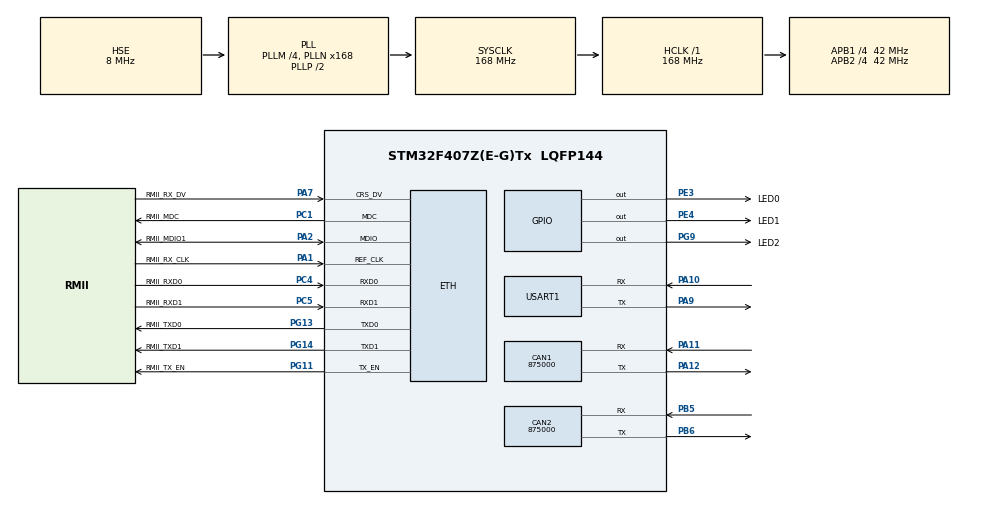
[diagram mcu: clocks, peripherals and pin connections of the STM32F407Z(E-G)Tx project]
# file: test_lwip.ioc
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CAN1.CalculateBaudRate=875000
CAN1.CalculateTimeBit=1142
CAN1.CalculateTimeQuantum=380.95238095238096
CAN2.CalculateBaudRate=875000
CAN2.CalculateTimeBit=1142
CAN2.CalculateTimeQuantum=380.95238095238096
Dma.Request0=USART1_RX
Dma.Request1=USART1_TX
Dma.USART1_RX.0.Direction=DMA_PERIPH_TO_MEMORY
Dma.USART1_RX.0.FIFOMode=DMA_FIFOMODE_DISABLE
Dma.USART1_RX.0.Instance=DMA2_Stream2
Dma.USART1_RX.0.MemDataAlignment=DMA_MDATAALIGN_BYTE
Dma.USART1_RX.0.MemInc=DMA_MINC_ENABLE
Dma.USART1_RX.0.Mode=DMA_NORMAL
Dma.USART1_RX.0.PeriphDataAlignment=DMA_PDATAALIGN_BYTE
Dma.USART1_RX.0.PeriphInc=DMA_PINC_DISABLE
Dma.USART1_RX.0.Priority=DMA_PRIORITY_LOW
Dma.USART1_TX.1.Direction=DMA_MEMORY_TO_PERIPH
Dma.USART1_TX.1.FIFOMode=DMA_FIFOMODE_DISABLE
Dma.USART1_TX.1.Instance=DMA2_Stream7
Dma.USART1_TX.1.MemDataAlignment=DMA_MDATAALIGN_BYTE
Dma.USART1_TX.1.MemInc=DMA_MINC_ENABLE
Dma.USART1_TX.1.Mode=DMA_NORMAL
Dma.USART1_TX.1.PeriphDataAlignment=DMA_PDATAALIGN_BYTE
Dma.USART1_TX.1.PeriphInc=DMA_PINC_DISABLE
Dma.USART1_TX.1.Priority=DMA_PRIORITY_LOW
ETH.MediaInterface=HAL_ETH_RMII_MODE
ETH.PHY_Name_RMII=DP83848_PHY_ADDRESS
FREERTOS.INCLUDE_vTaskDelayUntil=1
FREERTOS.Tasks01=defaultTask,0,256,StartDefaultTask,Default,NULL,Dynamic,NULL,NULL
FREERTOS.configMINIMAL_STACK_SIZE=256
LWIP.BSP.number=1
LWIP.GATEWAY_ADDRESS=010.043.060.001
LWIP.IP_ADDRESS=010.043.060.170
LWIP.LWIP_DHCP=0
LWIP.LWIP_NETIF_LOOPBACK=0
LWIP.MEM_SIZE=16360
LWIP.NETMASK_ADDRESS=255.255.255.000
LWIP.Version=v2.1.2_Cube
LWIP0.BSP.STBoard=false
LWIP0.BSP.api=BSP_COMPONENT_DRIVER
LWIP0.BSP.component=DP83848
LWIP0.BSP.instance=DP83848
LWIP0.BSP.name=Driver_PHY
LWIP0.BSP.semaphore=S_DP83848
LWIP0.BSP.solution=DP83848
Mcu.Family=STM32F4
Mcu.Name=STM32F407Z(E-G)Tx
Mcu.Package=LQFP144
NVIC.DMA2_Stream2_IRQn=true\:5\:0\:false\:false\:true\:true\:false\:true\:true
NVIC.DMA2_Stream7_IRQn=true\:5\:0\:false\:false\:true\:true\:false\:true\:true
NVIC.ETH_IRQn=true\:5\:0\:false\:false\:true\:true\:false\:true\:true
NVIC.PriorityGroup=NVIC_PRIORITYGROUP_4
NVIC.TIM4_IRQn=true\:15\:0\:false\:false\:true\:false\:false\:true\:true
NVIC.TimeBase=TIM4_IRQn
NVIC.TimeBaseIP=TIM4
NVIC.USART1_IRQn=true\:5\:0\:false\:false\:true\:true\:true\:true\:true
PA1.GPIO_Label=RMII_RX_CLK
PA1.Mode=RMII
PA1.Signal=ETH_REF_CLK
PA10.Mode=Asynchronous
PA10.Signal=USART1_RX
PA11.Mode=CAN_Activate
PA11.Signal=CAN1_RX
PA12.Mode=CAN_Activate
PA12.Signal=CAN1_TX
PA13.Mode=Trace_Asynchronous_SW
PA13.Signal=SYS_JTMS-SWDIO
PA14.Mode=Trace_Asynchronous_SW
PA14.Signal=SYS_JTCK-SWCLK
PA2.GPIO_Label=RMII_MDIO1
PA2.Mode=RMII
PA2.Signal=ETH_MDIO
PA7.GPIO_Label=RMII_RX_DV
PA7.Mode=RMII
PA7.Signal=ETH_CRS_DV
PA9.Mode=Asynchronous
PA9.Signal=USART1_TX
PB3.Mode=Trace_Asynchronous_SW
PB3.Signal=SYS_JTDO-SWO
PB5.Mode=CAN_Activate
PB5.Signal=CAN2_RX
PB6.Mode=CAN_Activate
PB6.Signal=CAN2_TX
PC1.GPIO_Label=RMII_MDC
PC1.Mode=RMII
PC1.Signal=ETH_MDC
PC14-OSC32_IN.Mode=LSE-External-Oscillator
PC14-OSC32_IN.Signal=RCC_OSC32_IN
PC15-OSC32_OUT.Mode=LSE-External-Oscillator
PC15-OSC32_OUT.Signal=RCC_OSC32_OUT
PC4.GPIO_Label=RMII_RXD0
PC4.Mode=RMII
PC4.Signal=ETH_RXD0
PC5.GPIO_Label=RMII_RXD1
PC5.Mode=RMII
PC5.Signal=ETH_RXD1
PE3.GPIO_Label=LED0
PE3.Signal=GPIO_Output
PE4.GPIO_Label=LED1
PE4.Signal=GPIO_Output
PG11.GPIO_Label=RMII_TX_EN
PG11.Mode=RMII
PG11.Signal=ETH_TX_EN
PG13.GPIO_Label=RMII_TXD0
PG13.Mode=RMII
PG13.Signal=ETH_TXD0
PG14.GPIO_Label=RMII_TXD1
PG14.Mode=RMII
PG14.Signal=ETH_TXD1
PG9.GPIO_Label=LED2
PG9.Signal=GPIO_Output
PH0-OSC_IN.Mode=HSE-External-Oscillator
PH0-OSC_IN.Signal=RCC_OSC_IN
PH1-OSC_OUT.Mode=HSE-External-Oscillator
PH1-OSC_OUT.Signal=RCC_OSC_OUT
ProjectManager.HeapSize=0x200
ProjectManager.StackSize=0x400
ProjectManager.TargetToolchain=Makefile
RCC.48MHZClocksFreq_Value=84000000
RCC.AHBFreq_Value=168000000
RCC.APB1CLKDivider=RCC_HCLK_DIV4
RCC.APB1Freq_Value=42000000
RCC.APB1TimFreq_Value=84000000
RCC.APB2CLKDivider=RCC_HCLK_DIV4
RCC.APB2Freq_Value=42000000
RCC.APB2TimFreq_Value=84000000
RCC.CortexFreq_Value=168000000
RCC.HCLKFreq_Value=168000000
RCC.HSE_VALUE=8000000
RCC.HSI_VALUE=16000000
RCC.PLLM=4
RCC.PLLN=168
RCC.PLLSourceVirtual=RCC_PLLSOURCE_HSE
RCC.SYSCLKFreq_VALUE=168000000
RCC.SYSCLKSource=RCC_SYSCLKSOURCE_PLLCLK
RCC.VCOOutputFreq_Value=336000000
USART1.VirtualMode=VM_ASYNC
VP_FREERTOS_VS_CMSIS_V1.Mode=CMSIS_V1
VP_LWIP_VS_Enabled.Mode=Enabled
VP_SYS_VS_tim4.Mode=TIM4
board=custom

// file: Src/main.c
/* USER CODE BEGIN Header */
/**
  ******************************************************************************
  * @file           : main.c
  * @brief          : Main program body
  ******************************************************************************
  * @attention
  *
  * Copyright (c) 2022 STMicroelectronics.
  * All rights reserved.
  *
  * This software is licensed under terms that can be found in the LICENSE file
  * in the root directory of this software component.
  * If no LICENSE file comes with this software, it is provided AS-IS.
  *
  ******************************************************************************
  */
/* USER CODE END Header */
#include "main.h"
#include "cmsis_os.h"
#include "can.h"
#include "dma.h"
#include "lwip.h"
#include "usart.h"
#include "gpio.h"

/* USER CODE BEGIN Includes */
#include "stdio.h"
/* USER CODE END Includes */

void SystemClock_Config(void);
void MX_FREERTOS_Init(void);

int main(void)
{

  /* MCU Configuration--------------------------------------------------------*/

  /* Reset of all peripherals, Initializes the Flash interface and the Systick. */
  HAL_Init();

  /* Configure the system clock */
  SystemClock_Config();

  /* Initialize all configured peripherals */
  MX_GPIO_Init();
  MX_DMA_Init();
  MX_CAN1_Init();
  MX_CAN2_Init();
  MX_USART1_UART_Init();

  /* Call init function for freertos objects (in freertos.c) */
  MX_FREERTOS_Init();

  /* Start scheduler */
  osKernelStart();

  /* We should never get here as control is now taken by the scheduler */
  /* Infinite loop */
  while (1)
  {

  }
}

void SystemClock_Config(void)
{
  RCC_OscInitTypeDef RCC_OscInitStruct = {0};
  RCC_ClkInitTypeDef RCC_ClkInitStruct = {0};

  /** Configure the main internal regulator output voltage
  */
  __HAL_RCC_PWR_CLK_ENABLE();
  __HAL_PWR_VOLTAGESCALING_CONFIG(PWR_REGULATOR_VOLTAGE_SCALE1);

  /** Initializes the RCC Oscillators according to the specified parameters
  * in the RCC_OscInitTypeDef structure.
  */
  RCC_OscInitStruct.OscillatorType = RCC_OSCILLATORTYPE_HSE;
  RCC_OscInitStruct.HSEState = RCC_HSE_ON;
  RCC_OscInitStruct.PLL.PLLState = RCC_PLL_ON;
  RCC_OscInitStruct.PLL.PLLSource = RCC_PLLSOURCE_HSE;
  RCC_OscInitStruct.PLL.PLLM = 4;
  RCC_OscInitStruct.PLL.PLLN = 168;
  RCC_OscInitStruct.PLL.PLLP = RCC_PLLP_DIV2;
  RCC_OscInitStruct.PLL.PLLQ = 4;
  if (HAL_RCC_OscConfig(&RCC_OscInitStruct) != HAL_OK)
  {
    Error_Handler();
  }

  /** Initializes the CPU, AHB and APB buses clocks
  */
  RCC_ClkInitStruct.ClockType = RCC_CLOCKTYPE_HCLK|RCC_CLOCKTYPE_SYSCLK
                              |RCC_CLOCKTYPE_PCLK1|RCC_CLOCKTYPE_PCLK2;
  RCC_ClkInitStruct.SYSCLKSource = RCC_SYSCLKSOURCE_PLLCLK;
  RCC_ClkInitStruct.AHBCLKDivider = RCC_SYSCLK_DIV1;
  RCC_ClkInitStruct.APB1CLKDivider = RCC_HCLK_DIV4;
  RCC_ClkInitStruct.APB2CLKDivider = RCC_HCLK_DIV4;

  if (HAL_RCC_ClockConfig(&RCC_ClkInitStruct, FLASH_LATENCY_5) != HAL_OK)
  {
    Error_Handler();
  }
}

void HAL_TIM_PeriodElapsedCallback(TIM_HandleTypeDef *htim)
{
  if (htim->Instance == TIM4) {
    HAL_IncTick();
  }
}

void Error_Handler(void)
{
  __disable_irq();
  while (1)
  {
  }
}

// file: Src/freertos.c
/* USER CODE BEGIN Header */
/**
  ******************************************************************************
  * File Name          : freertos.c
  * Description        : Code for freertos applications
  ******************************************************************************
  * @attention
  *
  * Copyright (c) 2022 STMicroelectronics.
  * All rights reserved.
  *
  * This software is licensed under terms that can be found in the LICENSE file
  * in the root directory of this software component.
  * If no LICENSE file comes with this software, it is provided AS-IS.
  *
  ******************************************************************************
  */
/* USER CODE END Header */

#include "FreeRTOS.h"
#include "task.h"
#include "main.h"
#include "cmsis_os.h"

/* USER CODE BEGIN Includes */
#include "stdio.h"
/* USER CODE END Includes */

osThreadId defaultTaskHandle;

void StartDefaultTask(void const * argument);

extern void MX_LWIP_Init(void);
void MX_FREERTOS_Init(void); /* (MISRA C 2004 rule 8.1) */

/* GetIdleTaskMemory prototype (linked to static allocation support) */
void vApplicationGetIdleTaskMemory( StaticTask_t **ppxIdleTaskTCBBuffer, StackType_t **ppxIdleTaskStackBuffer, uint32_t *pulIdleTaskStackSize );

/* USER CODE BEGIN GET_IDLE_TASK_MEMORY */
static StaticTask_t xIdleTaskTCBBuffer;
static StackType_t xIdleStack[configMINIMAL_STACK_SIZE];

void vApplicationGetIdleTaskMemory( StaticTask_t **ppxIdleTaskTCBBuffer, StackType_t **ppxIdleTaskStackBuffer, uint32_t *pulIdleTaskStackSize )
{
  *ppxIdleTaskTCBBuffer = &xIdleTaskTCBBuffer;
  *ppxIdleTaskStackBuffer = &xIdleStack[0];
  *pulIdleTaskStackSize = configMINIMAL_STACK_SIZE;
  /* place for user code */
}
/* USER CODE END GET_IDLE_TASK_MEMORY */

void MX_FREERTOS_Init(void) {

  /* Create the thread(s) */
  /* definition and creation of defaultTask */
  osThreadDef(defaultTask, StartDefaultTask, osPriorityNormal, 0, 256);
  defaultTaskHandle = osThreadCreate(osThread(defaultTask), NULL);

}

void StartDefaultTask(void const * argument)
{
  /* init code for LWIP */
  MX_LWIP_Init();
  /* USER CODE BEGIN StartDefaultTask */
  /* Infinite loop */
  for(;;)
  {
    HAL_GPIO_TogglePin(LED0_GPIO_Port,LED0_Pin);
    printf("%s(%d)\n", __func__, __LINE__);
    osDelay(1000);
  }
  /* USER CODE END StartDefaultTask */
}
